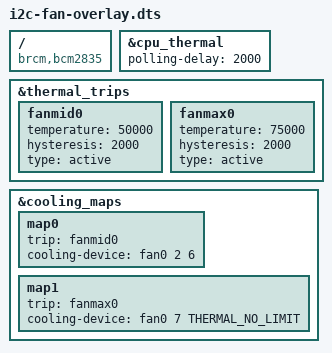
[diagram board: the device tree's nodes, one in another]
// Definitions for I2C based sensors using the Industrial IO or HWMON interface.
/dts-v1/;
/plugin/;

#include <dt-bindings/thermal/thermal.h>

#include "i2c-buses.dtsi"

/ {
	compatible = "brcm,bcm2835";

	fragment@0 {
		target = <&i2cbus>;
		__dormant__ {
			#address-cells = <1>;
			#size-cells = <0>;
			status = "okay";

			emc2301: emc2301@2f {
				compatible = "microchip,emc2301", "microchip,emc2305";
				reg = <0x2f>;
				#pwm-cells = <3>;

				fan0: fan@0 {
					reg = <0x0>;
					pwms = <&emc2301 26000 0 1>;
					#cooling-cells = <2>;
				};

			};
		};
	};

	fragment@1 {
		target = <&cpu_thermal>;
		__overlay__ {
			polling-delay = <2000>; /* milliseconds */
		};
	};

	fragment@2 {
		target = <&thermal_trips>;
		__overlay__ {
			fanmid0: fanmid0 {
				temperature = <50000>;
				hysteresis = <2000>;
				type = "active";
			};
			fanmax0: fanmax0 {
				temperature = <75000>;
				hysteresis = <2000>;
				type = "active";
			};
		};
	};

	fragment@3 {
		target = <&cooling_maps>;
		__overlay__ {
			map0: map0 {
				trip = <&fanmid0>;
				cooling-device = <&fan0 2 6>;
			};
			map1: map1 {
				trip = <&fanmax0>;
				cooling-device = <&fan0 7 THERMAL_NO_LIMIT>;
			};
		};
	};

	__overrides__ {
		addr =		<&emc2301>,"reg:0";
		midtemp =	<&fanmid0>,"temperature:0";
		midtemp_hyst =	<&fanmid0>,"hysteresis:0";
		maxtemp =	<&fanmax0>,"temperature:0";
		maxtemp_hyst =	<&fanmax0>,"hysteresis:0";

		emc2301 =	<0>,"+0",
				<&map0>,"cooling-device:0=",<&fan0>,
				<&map1>,"cooling-device:0=",<&fan0>;
	};
};
